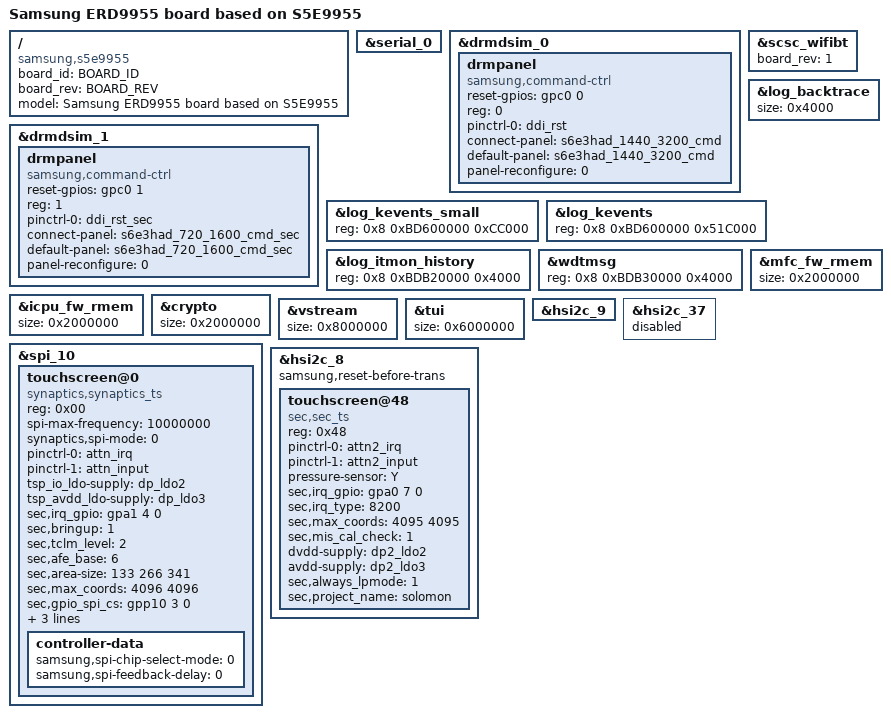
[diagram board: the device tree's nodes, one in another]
/*
 * SAMSUNG S5E9955 board device tree source
 *
 * Copyright (c) 2023 Samsung Electronics Co., Ltd.
 *		http://www.samsung.com
 *
 * This program is free software; you can redistribute it and/or modify
 * it under the terms of the GNU General Public License version 2 as
 * published by the Free Software Foundation.
 */

/dts-v1/;
/plugin/;

#include "s5e9955-erd9955_common.dtsi"
#include <dt-bindings/gpio/gpio.h>
#include "panel/samsung-s6e3had-720-1600-command-panel-sec.dtsi"
#include "panel/samsung-s6e3haf-1080-2340-panel.dtsi"

#define BOARD_ID	0x0
#define BOARD_REV	0x3

/ {
	compatible = "samsung,s5e9955", "samsung,ERD9955";
	board_id = <BOARD_ID>;
	board_rev = <BOARD_REV>;

	fragment@model {
		target-path = "/";
		__overlay__ {
			#address-cells = <2>;
			#size-cells = <1>;

			model = "Samsung ERD9955 board based on S5E9955";
		}; /* end of __overlay__ */
	}; /* end of fragment */
}; /* end of root */

&serial_0 {
	status = "okay";
};

&drmdsim_0 {
	#address-cells = <1>;
	#size-cells = <0>;
	drmpanel {
		compatible = "samsung,command-ctrl";
		/* reset, power */
		reset-gpios = <&gpc0 0 GPIO_ACTIVE_HIGH>;
		reg = <0>;
		pinctrl-names = "default";
		pinctrl-0 = <&ddi_rst>;

		connect-panel = "s6e3had_1440_3200_cmd";
		default-panel = "s6e3had_1440_3200_cmd";
		panel-reconfigure = <0>;
	};
};

&drmdsim_1 {
	#address-cells = <1>;
	#size-cells = <0>;
	drmpanel {
		compatible = "samsung,command-ctrl";
		/* reset, power */
		reset-gpios = <&gpc0 1 GPIO_ACTIVE_HIGH>;
		reg = <1>;
		pinctrl-names = "default";
		pinctrl-0 = <&ddi_rst_sec>;

		connect-panel = "s6e3had_720_1600_cmd_sec";
		default-panel = "s6e3had_720_1600_cmd_sec";
		panel-reconfigure = <0>;
	};
};

&scsc_wifibt {
	board_rev = <1>;
};

&log_kevents_small {
	reg = <0x8 0xBD600000 0xCC000>;
};

&log_backtrace {
	size = <0x4000>;
};

&log_kevents {
	reg = <0x8 0xBD600000 0x51C000>;
};

&log_itmon_history {
	reg = <0x8 0xBDB20000 0x4000>;
};

&wdtmsg {
	reg = <0x8 0xBDB30000 0x4000>;
};

&mfc_fw_rmem {
	size = <0x2000000>;
};

&icpu_fw_rmem {
	size = <0x2000000>;
};

&crypto {
	size = <0x2000000>;
};

&vstream {
	size = <0x8000000>;
};

&tui {
	size = <0x6000000>;
};

/* second display pmic */
&hsi2c_9 {
	status = "okay";
};

/* Main Touch */
&hsi2c_37 {
	status = "disabled";
};

&spi_10 {
	#address-cells = <1>;
	#size-cells = <0>;
	status = "okay";

	touchscreen@0{
		status = "okay";
		compatible = "synaptics,synaptics_ts";
		reg = <0x00>;
		spi-max-frequency = <10000000>;
		synaptics,spi-mode = <0>;
		pinctrl-names = "on_state", "off_state";
		pinctrl-0 = <&attn_irq>;
		pinctrl-1 = <&attn_input>;
		tsp_io_ldo-supply = <&dp_ldo2>;
		tsp_avdd_ldo-supply = <&dp_ldo3>;
		sec,irq_gpio = <&gpa1 4 0>;
		sec,bringup = <1>;
		//sec,regulator_boot_on;
		sec,tclm_level = <2>;
		sec,afe_base = <6>;
		sec,area-size = <133 266 341>;
		sec,max_coords = <4096 4096>;
		sec,gpio_spi_cs = <&gpp10 3 0>;
		work_queue_probe_enabled;
		synaptics,fw_delay = <6 120>;
		synaptics,power_on_delay = <100>;

		controller-data {
			//samsung,spi-cs-stream;
			samsung,spi-chip-select-mode = <0>;
			samsung,spi-feedback-delay= <0>;
		};
	};
};

/* Sub Touch */
&hsi2c_8 {
	#address-cells = <1>;
	#size-cells = <0>;
	status = "okay";
	samsung,reset-before-trans;
	touchscreen@48 {
		compatible = "sec,sec_ts";
		reg = <0x48>;
		pinctrl-names = "on_state", "off_state";
		pinctrl-0 = <&attn2_irq>;
		pinctrl-1 = <&attn2_input>;
		pressure-sensor = "Y";
		sec,irq_gpio = <&gpa0 7 0>;
		sec,irq_type = <8200>;
		sec,max_coords = <4095 4095>;
		sec,mis_cal_check = <1>;
		dvdd-supply = <&dp2_ldo2>;// VDD_TSP0_1P8
		avdd-supply = <&dp2_ldo3>;// VDD_TSP0_3P0
		sec,always_lpmode = <1>;
		sec,project_name = "solomon";
	};
};
